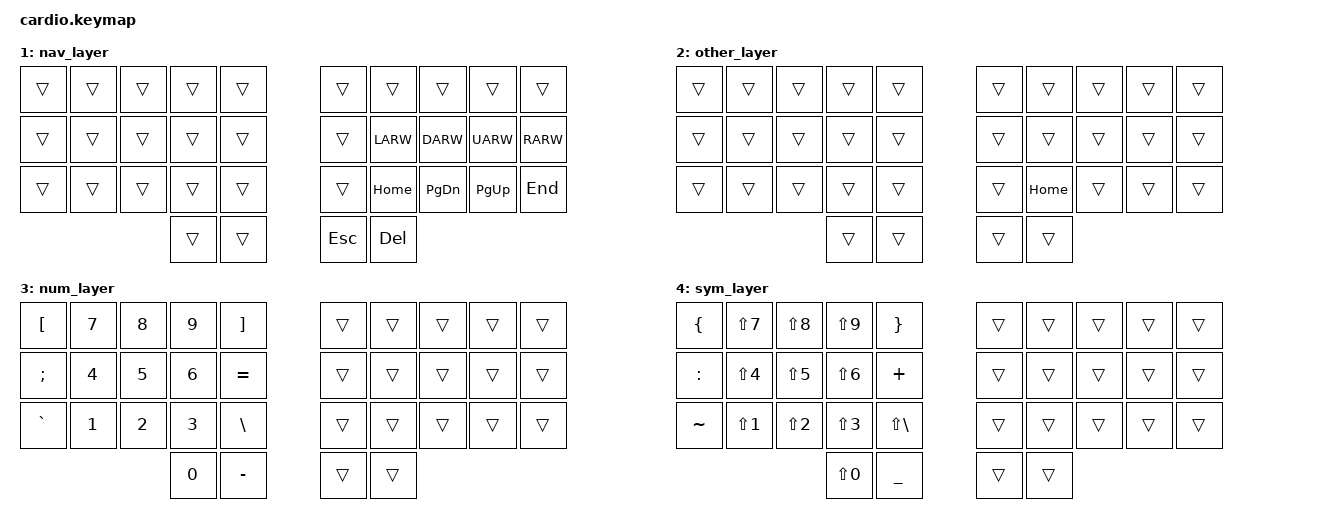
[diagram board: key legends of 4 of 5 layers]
/*
 * Copyright (c) 2020 The ZMK Contributors
 *
 * SPDX-License-Identifier: MIT
 */

#include <behaviors.dtsi>
#include <dt-bindings/zmk/keys.h>
#include <dt-bindings/zmk/bt.h>
// #include <dt-bindings/zmk/mouse.h>

#define NAV_L 1
#define OTHER_L 2
#define NUM_L 3
#define SYM_L 4

&mt {
    flavor = "tap-preferred";
    tapping_term_ms = <200>;
};

/ {
    combos {
        compatible = "zmk,combos";
        combo_esc {
            timeout-ms = <50>;
            key-positions = <0 1>;
            bindings = <&kp ESC>;
        };
        
         combo_tab {
            timeout-ms = <50>;
            key-positions = <11 12>;
            bindings = <&kp TAB>;
        };
        
        combo_ent {
            timeout-ms = <50>;
	        key-positions = <27 28>;
            bindings = <&kp RET>;
        };

        combo_ent {
            timeout-ms = <50>;
	        key-positions = <8 9>;
            bindings = <&kp BSPC>;
        };
        
                    combo_lalt {
            timeout-ms = <50>;
            key-positions = <11 12>;
            bindings = <&kp LALT>;
        };
        
                           combo_lgui {
            timeout-ms = <50>;
            key-positions = <12 13>;
            bindings = <&kp LGUI>;
        };
        
        
           combo_rgui {
            timeout-ms = <50>;
            key-positions = <17 18>;
            bindings = <&kp RGUI>;
        };     
    };

    behaviors {
        hm: homerow_mods {
            compatible = "zmk,behavior-hold-tap";
            label = "homerow mods";
            #binding-cells = <2>;
            tapping_term_ms = <200>;
            quick_tap_ms = <0>;
            flavor = "tap-preferred";
            bindings = <&kp>, <&kp>;
        };
        hs: homerow_shifts {
            compatible = "zmk,behavior-hold-tap";
            label = "HOMEROW_SHIFTS";
            #binding-cells = <2>;
            tapping-term-ms = <150>;
            quick_tap_ms = <0>;
            flavor = "balanced";
            bindings = <&kp>, <&kp>;
        };
        hsl: homerow_shifts_layer {
            compatible = "zmk,behavior-hold-tap";
            label = "HOMEROW_SHIFTS_LAYER";
            #binding-cells = <2>;
            tapping-term-ms = <150>;
            quick_tap_ms = <0>;
            flavor = "balanced";
            bindings = <&kp>, <&to>;
        };
        td: tapdance {
            compatible = "zmk,behavior-hold-tap";
            label = "TAPDANCE";
            #binding-cells = <2>;
            tapping-term-ms = <150>;
            quick_tap_ms = <0>;
            flavor = "tap-preferred";
            bindings = <&kp>, <&kp>;
        };
	    bl: layertap {
            compatible = "zmk,behavior-hold-tap";
            label = "LAYERTAP";
            #binding-cells = <2>;
            tapping-term-ms = <150>;
            quick_tap_ms = <0>;
            flavor = "tap-preferred";
            bindings = <&to>, <&kp>;
        };
    };

    keymap {
        compatible = "zmk,keymap";

        default_layer {
            bindings = <
                &kp Q        &kp D      &kp R      &kp W &kp B     &kp J &kp F  &kp U     &kp P   &kp ;
                &kp A        &hm LCTL S &hm LALT H &kp T &kp G     &kp Y &kp N  &kp E     &kp O   &kp I      
                &hs LSHIFT Z &kp X      &kp M      &kp C &kp V     &kp K &kp L  &kp COMMA &kp DOT &hs RSHIFT FSLH
                            &mt NAV_L TAB  &kp RET     &mt NUM_L SPACE  &mt SYM_L BKSP
            >;
        };

        nav_layer {
            bindings = <
                &trans     &trans     &trans      &trans          &trans       &trans           &trans         &trans      &trans     &trans
                &trans     &trans     &trans      &trans          &trans       &trans           &kp LARW       &kp DARW    &kp UARW   &kp RARW
                &trans     &trans     &trans      &trans          &trans       &trans           &kp HOME       &kp PG_DN   &kp PG_UP  &kp END
                                                  &trans          &trans       &kp ESC          &kp DEL
            >;
        };

        other_layer {
            bindings = <
                &trans     &trans     &trans      &trans          &trans       &trans           &trans         &trans      &trans     &trans
                &trans     &trans     &trans      &trans          &trans       &trans           &trans         &trans      &trans     &trans
                &trans     &trans     &trans      &trans          &trans       &trans           &kp HOME       &trans      &trans     &trans
                                                  &trans          &trans       &trans           &trans
            >;
        };

        num_layer {
            bindings = <
                &kp LBKT   &kp N7     &kp N8      &kp N9          &kp RBKT      &trans          &trans         &trans      &trans     &trans
                &kp SEMI   &kp N4     &kp N5      &kp N6          &kp EQUAL     &trans          &trans         &trans      &trans     &trans
                &kp GRAVE  &kp N1     &kp N2      &kp N3          &kp BSLH      &trans          &trans         &trans      &trans     &trans
                                                  &kp N0          &kp MINUS     &trans          &trans
            >;
        };

        sym_layer {
            bindings = <
                &kp LBRC     &kp LS(N7)  &kp LS(N8)  &kp LS(N9) &kp RBRC       &trans &trans   &trans    &trans    &trans
                &kp COLON     &kp LS(N4)  &kp LS(N5)  &kp LS(N6) &kp PLUS       &trans &trans   &trans    &trans    &trans
                &kp TILDE     &kp LS(N1)  &kp LS(N2)  &kp LS(N3) &kp LS(BSLH)       &trans &trans   &trans    &trans    &trans
                                                   &kp LS(N0) &kp UNDER   &trans &trans
            >;
        };
    };
};
